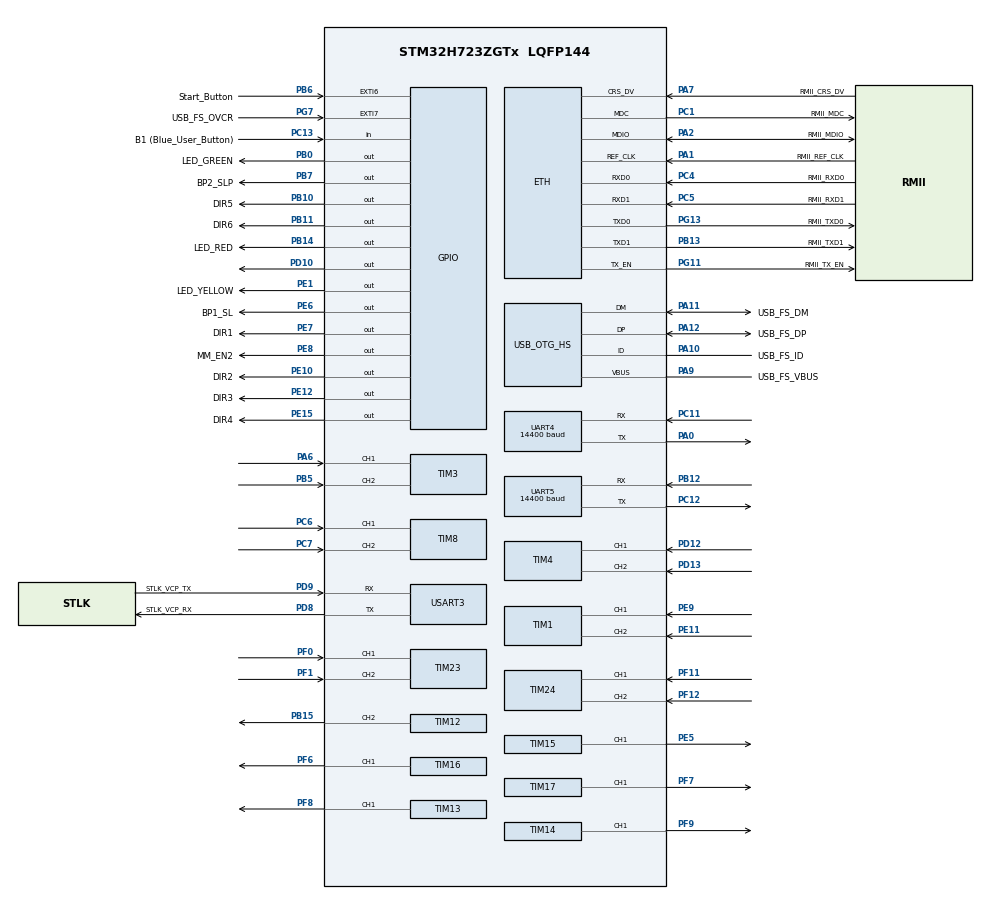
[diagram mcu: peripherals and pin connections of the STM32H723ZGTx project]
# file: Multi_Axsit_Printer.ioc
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Dma.Request0=UART4_RX
Dma.Request1=UART4_TX
Dma.Request2=UART5_RX
Dma.Request3=UART5_TX
Dma.UART4_RX.0.Direction=DMA_PERIPH_TO_MEMORY
Dma.UART4_RX.0.EventEnable=DISABLE
Dma.UART4_RX.0.FIFOMode=DMA_FIFOMODE_DISABLE
Dma.UART4_RX.0.Instance=DMA1_Stream0
Dma.UART4_RX.0.MemDataAlignment=DMA_MDATAALIGN_BYTE
Dma.UART4_RX.0.MemInc=DMA_MINC_ENABLE
Dma.UART4_RX.0.Mode=DMA_NORMAL
Dma.UART4_RX.0.PeriphDataAlignment=DMA_PDATAALIGN_BYTE
Dma.UART4_RX.0.PeriphInc=DMA_PINC_DISABLE
Dma.UART4_RX.0.Polarity=HAL_DMAMUX_REQ_GEN_RISING
Dma.UART4_RX.0.Priority=DMA_PRIORITY_LOW
Dma.UART4_RX.0.RequestNumber=1
Dma.UART4_RX.0.SignalID=NONE
Dma.UART4_RX.0.SyncEnable=DISABLE
Dma.UART4_RX.0.SyncPolarity=HAL_DMAMUX_SYNC_NO_EVENT
Dma.UART4_RX.0.SyncRequestNumber=1
Dma.UART4_RX.0.SyncSignalID=NONE
Dma.UART4_TX.1.Direction=DMA_MEMORY_TO_PERIPH
Dma.UART4_TX.1.EventEnable=DISABLE
Dma.UART4_TX.1.FIFOMode=DMA_FIFOMODE_DISABLE
Dma.UART4_TX.1.Instance=DMA1_Stream1
Dma.UART4_TX.1.MemDataAlignment=DMA_MDATAALIGN_BYTE
Dma.UART4_TX.1.MemInc=DMA_MINC_ENABLE
Dma.UART4_TX.1.Mode=DMA_NORMAL
Dma.UART4_TX.1.PeriphDataAlignment=DMA_PDATAALIGN_BYTE
Dma.UART4_TX.1.PeriphInc=DMA_PINC_DISABLE
Dma.UART4_TX.1.Polarity=HAL_DMAMUX_REQ_GEN_RISING
Dma.UART4_TX.1.Priority=DMA_PRIORITY_LOW
Dma.UART4_TX.1.RequestNumber=1
Dma.UART4_TX.1.SignalID=NONE
Dma.UART4_TX.1.SyncEnable=DISABLE
Dma.UART4_TX.1.SyncPolarity=HAL_DMAMUX_SYNC_NO_EVENT
Dma.UART4_TX.1.SyncRequestNumber=1
Dma.UART4_TX.1.SyncSignalID=NONE
Dma.UART5_RX.2.Direction=DMA_PERIPH_TO_MEMORY
Dma.UART5_RX.2.EventEnable=DISABLE
Dma.UART5_RX.2.FIFOMode=DMA_FIFOMODE_DISABLE
Dma.UART5_RX.2.Instance=DMA1_Stream2
Dma.UART5_RX.2.MemDataAlignment=DMA_MDATAALIGN_BYTE
Dma.UART5_RX.2.MemInc=DMA_MINC_ENABLE
Dma.UART5_RX.2.Mode=DMA_NORMAL
Dma.UART5_RX.2.PeriphDataAlignment=DMA_PDATAALIGN_BYTE
Dma.UART5_RX.2.PeriphInc=DMA_PINC_DISABLE
Dma.UART5_RX.2.Polarity=HAL_DMAMUX_REQ_GEN_RISING
Dma.UART5_RX.2.Priority=DMA_PRIORITY_LOW
Dma.UART5_RX.2.RequestNumber=1
Dma.UART5_RX.2.SignalID=NONE
Dma.UART5_RX.2.SyncEnable=DISABLE
Dma.UART5_RX.2.SyncPolarity=HAL_DMAMUX_SYNC_NO_EVENT
Dma.UART5_RX.2.SyncRequestNumber=1
Dma.UART5_RX.2.SyncSignalID=NONE
Dma.UART5_TX.3.Direction=DMA_MEMORY_TO_PERIPH
Dma.UART5_TX.3.EventEnable=DISABLE
Dma.UART5_TX.3.FIFOMode=DMA_FIFOMODE_DISABLE
Dma.UART5_TX.3.Instance=DMA1_Stream3
Dma.UART5_TX.3.MemDataAlignment=DMA_MDATAALIGN_BYTE
Dma.UART5_TX.3.MemInc=DMA_MINC_ENABLE
Dma.UART5_TX.3.Mode=DMA_NORMAL
Dma.UART5_TX.3.PeriphDataAlignment=DMA_PDATAALIGN_BYTE
Dma.UART5_TX.3.PeriphInc=DMA_PINC_DISABLE
Dma.UART5_TX.3.Polarity=HAL_DMAMUX_REQ_GEN_RISING
Dma.UART5_TX.3.Priority=DMA_PRIORITY_LOW
Dma.UART5_TX.3.RequestNumber=1
Dma.UART5_TX.3.SignalID=NONE
Dma.UART5_TX.3.SyncEnable=DISABLE
Dma.UART5_TX.3.SyncPolarity=HAL_DMAMUX_SYNC_NO_EVENT
Dma.UART5_TX.3.SyncRequestNumber=1
Dma.UART5_TX.3.SyncSignalID=NONE
ETH.MediaInterface=HAL_ETH_RMII_MODE
Mcu.Family=STM32H7
Mcu.Name=STM32H723ZGTx
Mcu.Package=LQFP144
NVIC.DMA1_Stream0_IRQn=true\:0\:0\:false\:false\:true\:false\:true\:true
NVIC.DMA1_Stream1_IRQn=true\:0\:0\:false\:false\:true\:false\:true\:true
NVIC.DMA1_Stream2_IRQn=true\:0\:0\:false\:false\:true\:false\:true\:true
NVIC.DMA1_Stream3_IRQn=true\:0\:0\:false\:false\:true\:false\:true\:true
NVIC.EXTI9_5_IRQn=true\:0\:0\:false\:false\:true\:true\:true\:true
NVIC.PriorityGroup=NVIC_PRIORITYGROUP_4
NVIC.TIM5_IRQn=true\:0\:0\:false\:false\:true\:true\:true\:true
NVIC.UART4_IRQn=true\:0\:0\:false\:false\:true\:true\:true\:true
NVIC.UART5_IRQn=true\:0\:0\:false\:false\:true\:true\:true\:true
PA0.Mode=Asynchronous
PA0.Signal=UART4_TX
PA1.GPIO_Label=RMII_REF_CLK
PA1.Mode=RMII
PA1.Signal=ETH_REF_CLK
PA10.GPIO_Label=USB_FS_ID
PA10.Mode=OTG/Dual-Role-Device-FS
PA10.Signal=USB_OTG_HS_ID
PA11.GPIO_Label=USB_FS_DM
PA11.Mode=OTG/Dual-Role-Device-FS
PA11.Signal=USB_OTG_HS_DM
PA12.GPIO_Label=USB_FS_DP
PA12.Mode=OTG/Dual-Role-Device-FS
PA12.Signal=USB_OTG_HS_DP
PA13(JTMS/SWDIO).GPIO_Label=SWDIO
PA13(JTMS/SWDIO).Mode=Trace_Asynchronous_SW
PA13(JTMS/SWDIO).Signal=DEBUG_JTMS-SWDIO
PA14(JTCK/SWCLK).GPIO_Label=SWCLK
PA14(JTCK/SWCLK).Mode=Trace_Asynchronous_SW
PA14(JTCK/SWCLK).Signal=DEBUG_JTCK-SWCLK
PA2.GPIO_Label=RMII_MDIO
PA2.Mode=RMII
PA2.Signal=ETH_MDIO
PA6.Signal=S_TIM3_CH1
PA7.GPIO_Label=RMII_CRS_DV
PA7.Mode=RMII
PA7.Signal=ETH_CRS_DV
PA9.GPIO_Label=USB_FS_VBUS
PA9.Mode=Activate_VBUS_FS
PA9.Signal=USB_OTG_HS_VBUS
PB0.GPIO_Label=LED_GREEN
PB0.Signal=GPIO_Output
PB10.GPIO_Label=DIR5
PB10.Signal=GPIO_Output
PB11.GPIO_Label=DIR6
PB11.Signal=GPIO_Output
PB12.Mode=Asynchronous
PB12.Signal=UART5_RX
PB13.GPIO_Label=RMII_TXD1
PB13.Mode=RMII
PB13.Signal=ETH_TXD1
PB14.GPIO_Label=LED_RED
PB14.Signal=GPIO_Output
PB15.Signal=S_TIM12_CH2
PB3(JTDO/TRACESWO).GPIO_Label=SWO
PB3(JTDO/TRACESWO).Mode=Trace_Asynchronous_SW
PB3(JTDO/TRACESWO).Signal=DEBUG_JTDO-SWO
PB5.Signal=S_TIM3_CH2
PB6.GPIO_Label=Start_Button
PB6.GPIO_PuPd=GPIO_PULLDOWN
PB6.Signal=GPXTI6
PB7.GPIO_Label=BP2_SLP
PB7.Signal=GPIO_Output
PC1.GPIO_Label=RMII_MDC
PC1.Mode=RMII
PC1.Signal=ETH_MDC
PC11.Mode=Asynchronous
PC11.Signal=UART4_RX
PC12.Mode=Asynchronous
PC12.Signal=UART5_TX
PC13.GPIO_Label=B1 (Blue_User_Button)
PC13.Signal=GPIO_Input
PC14-OSC32_IN.Mode=LSE-External-Oscillator
PC14-OSC32_IN.Signal=RCC_OSC32_IN
PC15-OSC32_OUT.Mode=LSE-External-Oscillator
PC15-OSC32_OUT.Signal=RCC_OSC32_OUT
PC4.GPIO_Label=RMII_RXD0
PC4.Mode=RMII
PC4.Signal=ETH_RXD0
PC5.GPIO_Label=RMII_RXD1
PC5.Mode=RMII
PC5.Signal=ETH_RXD1
PC6.Signal=S_TIM8_CH1
PC7.Signal=S_TIM8_CH2
PD10.Signal=GPIO_Output
PD12.Signal=S_TIM4_CH1
PD13.Signal=S_TIM4_CH2
PD8.GPIO_Label=STLK_VCP_RX
PD8.Mode=Asynchronous
PD8.Signal=USART3_TX
PD9.GPIO_Label=STLK_VCP_TX
PD9.Mode=Asynchronous
PD9.Signal=USART3_RX
PE1.GPIO_Label=LED_YELLOW
PE1.Signal=GPIO_Output
PE10.GPIO_Label=DIR2
PE10.Signal=GPIO_Output
PE11.Signal=S_TIM1_CH2
PE12.GPIO_Label=DIR3
PE12.Signal=GPIO_Output
PE15.GPIO_Label=DIR4
PE15.Signal=GPIO_Output
PE5.Signal=S_TIM15_CH1
PE6.GPIO_Label=BP1_SL
PE6.Signal=GPIO_Output
PE7.GPIO_Label=DIR1
PE7.Signal=GPIO_Output
PE8.GPIO_Label=MM_EN2
PE8.Signal=GPIO_Output
PE9.Signal=S_TIM1_CH1
PF0.Mode=Encoder_Interface
PF0.Signal=TIM23_CH1
PF1.Signal=S_TIM23_CH2
PF11.Mode=Encoder_Interface
PF11.Signal=TIM24_CH1
PF12.Signal=S_TIM24_CH2
PF6.Signal=S_TIM16_CH1
PF7.Signal=S_TIM17_CH1
PF8.Signal=S_TIM13_CH1
PF9.Signal=S_TIM14_CH1
PG11.GPIO_Label=RMII_TX_EN
PG11.Mode=RMII
PG11.Signal=ETH_TX_EN
PG13.GPIO_Label=RMII_TXD0
PG13.Mode=RMII
PG13.Signal=ETH_TXD0
PG7.GPIO_Label=USB_FS_OVCR
PG7.Signal=GPXTI7
PH0-OSC_IN.GPIO_Label=MCO
PH0-OSC_IN.Mode=HSE-External-Clock-Source
PH0-OSC_IN.Signal=RCC_OSC_IN
PH1-OSC_OUT.Signal=RCC_OSC_OUT
ProjectManager.HeapSize=0x200
ProjectManager.StackSize=0x400
ProjectManager.TargetToolchain=STM32CubeIDE
RCC.ADCFreq_Value=76000000
RCC.APB1Freq_Value=137500000
RCC.APB2Freq_Value=137500000
RCC.APB3Freq_Value=137500000
RCC.APB4Freq_Value=137500000
RCC.CortexFreq_Value=550000000
RCC.D1PPRE=RCC_APB3_DIV2
RCC.D2PPRE1=RCC_APB1_DIV2
RCC.D2PPRE2=RCC_APB2_DIV2
RCC.D3PPRE=RCC_APB4_DIV2
RCC.DIVM1=4
RCC.DIVM2=1
RCC.DIVN1=275
RCC.DIVN2=19
RCC.DIVP1=1
RCC.DIVQ1=4
RCC.HCLKFreq_Value=275000000
RCC.HPRE=RCC_HCLK_DIV2
RCC.HSE_VALUE=8000000
RCC.PLLFRACN=0
RCC.PLLSourceVirtual=RCC_PLLSOURCE_HSE
RCC.SYSCLKFreq_VALUE=550000000
RCC.SYSCLKSource=RCC_SYSCLKSOURCE_PLLCLK
RCC.USBCLockSelection=RCC_USBCLKSOURCE_HSI48
RCC.USBFreq_Value=48000000
SH.S_TIM12_CH2.0=TIM12_CH2,PWM Generation2 CH2
SH.S_TIM13_CH1.0=TIM13_CH1,PWM Generation1 CH1
SH.S_TIM14_CH1.0=TIM14_CH1,PWM Generation1 CH1
SH.S_TIM15_CH1.0=TIM15_CH1,PWM Generation1 CH1
SH.S_TIM16_CH1.0=TIM16_CH1,PWM Generation1 CH1
SH.S_TIM17_CH1.0=TIM17_CH1,PWM Generation1 CH1
SH.S_TIM1_CH1.0=TIM1_CH1,Encoder_Interface
SH.S_TIM1_CH2.0=TIM1_CH2,Encoder_Interface
SH.S_TIM23_CH2.0=TIM23_CH2,Encoder_Interface
SH.S_TIM24_CH2.0=TIM24_CH2,Encoder_Interface
SH.S_TIM3_CH1.0=TIM3_CH1,Encoder_Interface
SH.S_TIM3_CH2.0=TIM3_CH2,Encoder_Interface
SH.S_TIM4_CH1.0=TIM4_CH1,Encoder_Interface
SH.S_TIM4_CH2.0=TIM4_CH2,Encoder_Interface
SH.S_TIM8_CH1.0=TIM8_CH1,Encoder_Interface
SH.S_TIM8_CH2.0=TIM8_CH2,Encoder_Interface
TIM1.EncoderMode=TIM_ENCODERMODE_TI12
TIM12.Channel-PWM\ Generation2\ CH2=TIM_CHANNEL_2
TIM12.Period=1250-1
TIM12.Prescaler=11-1
TIM13.Channel=TIM_CHANNEL_1
TIM13.Period=1250-1
TIM13.Prescaler=11-1
TIM14.Channel=TIM_CHANNEL_1
TIM14.Period=1250-1
TIM14.Prescaler=440-1
TIM15.Channel-PWM\ Generation1\ CH1=TIM_CHANNEL_1
TIM15.Period=1250-1
TIM15.Prescaler=440-1
TIM16.Channel=TIM_CHANNEL_1
TIM16.Period=1250-1
TIM16.Prescaler=440-1
TIM17.Channel=TIM_CHANNEL_1
TIM17.Period=1250-1
TIM17.Prescaler=440-1
TIM23.EncoderMode=TIM_ENCODERMODE_TI12
TIM24.EncoderMode=TIM_ENCODERMODE_TI12
TIM3.EncoderMode=TIM_ENCODERMODE_TI12
TIM4.EncoderMode=TIM_ENCODERMODE_TI12
TIM5.Period=49999
TIM5.Prescaler=274
TIM8.EncoderMode=TIM_ENCODERMODE_TI12
UART4.BaudRate=14400
UART5.BaudRate=14400
USART3.VirtualMode-Asynchronous=VM_ASYNC
VP_MEMORYMAP_VS_MEMORYMAP.Mode=CurAppReg
VP_TIM13_VS_ClockSourceINT.Mode=Enable_Timer
VP_TIM14_VS_ClockSourceINT.Mode=Enable_Timer
VP_TIM16_VS_ClockSourceINT.Mode=Enable_Timer
VP_TIM17_VS_ClockSourceINT.Mode=Enable_Timer
VP_TIM5_VS_ClockSourceINT.Mode=Internal
board=NUCLEO-H723ZG

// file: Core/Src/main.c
/* USER CODE BEGIN Header */
/**
 ******************************************************************************
 * @file           : main.c
 * @brief          : Main program body
 ******************************************************************************
 * @attention
 *
 * Copyright (c) 2024 STMicroelectronics.
 * All rights reserved.
 *
 * This software is licensed under terms that can be found in the LICENSE file
 * in the root directory of this software component.
 * If no LICENSE file comes with this software, it is provided AS-IS.
 *
 ******************************************************************************
 */
/* USER CODE END Header */
#include "main.h"
#include "dma.h"
#include "eth.h"
#include "memorymap.h"
#include "tim.h"
#include "usart.h"
#include "usb_otg.h"
#include "gpio.h"

/* USER CODE BEGIN Includes */
#include "mainpp.h"
/* USER CODE END Includes */

void SystemClock_Config(void);

/* USER CODE BEGIN 0 */
int _write(int file, char *ptr, int len) {
	for (int i = 0; i < len; i++) ITM_SendChar((*ptr++));
	return len;
}
/* USER CODE END 0 */

int main(void)
{

  /* MCU Configuration--------------------------------------------------------*/

  /* Reset of all peripherals, Initializes the Flash interface and the Systick. */
  HAL_Init();

  /* Configure the system clock */
  SystemClock_Config();

  /* Initialize all configured peripherals */
  MX_GPIO_Init();
  MX_DMA_Init();
  MX_USB_OTG_HS_USB_Init();
  MX_UART4_Init();
  MX_ETH_Init();
  MX_TIM1_Init();
  MX_TIM3_Init();
  MX_TIM4_Init();
  MX_TIM8_Init();
  MX_TIM13_Init();
  MX_TIM14_Init();
  MX_TIM15_Init();
  MX_TIM16_Init();
  MX_TIM17_Init();
  MX_TIM23_Init();
  MX_TIM24_Init();
  MX_TIM12_Init();
  MX_USART3_UART_Init();
  MX_UART5_Init();
  MX_TIM5_Init();
  /* USER CODE BEGIN 2 */
	main_function();
  /* USER CODE END 2 */

  /* Infinite loop */
	while (1) {

	}
}

void SystemClock_Config(void)
{
  RCC_OscInitTypeDef RCC_OscInitStruct = {0};
  RCC_ClkInitTypeDef RCC_ClkInitStruct = {0};

  /** Supply configuration update enable
  */
  HAL_PWREx_ConfigSupply(PWR_LDO_SUPPLY);

  /** Configure the main internal regulator output voltage
  */
  __HAL_PWR_VOLTAGESCALING_CONFIG(PWR_REGULATOR_VOLTAGE_SCALE0);

  while(!__HAL_PWR_GET_FLAG(PWR_FLAG_VOSRDY)) {}

  /** Initializes the RCC Oscillators according to the specified parameters
  * in the RCC_OscInitTypeDef structure.
  */
  RCC_OscInitStruct.OscillatorType = RCC_OSCILLATORTYPE_HSI48|RCC_OSCILLATORTYPE_HSE;
  RCC_OscInitStruct.HSEState = RCC_HSE_BYPASS;
  RCC_OscInitStruct.HSI48State = RCC_HSI48_ON;
  RCC_OscInitStruct.PLL.PLLState = RCC_PLL_ON;
  RCC_OscInitStruct.PLL.PLLSource = RCC_PLLSOURCE_HSE;
  RCC_OscInitStruct.PLL.PLLM = 4;
  RCC_OscInitStruct.PLL.PLLN = 275;
  RCC_OscInitStruct.PLL.PLLP = 1;
  RCC_OscInitStruct.PLL.PLLQ = 4;
  RCC_OscInitStruct.PLL.PLLR = 2;
  RCC_OscInitStruct.PLL.PLLRGE = RCC_PLL1VCIRANGE_1;
  RCC_OscInitStruct.PLL.PLLVCOSEL = RCC_PLL1VCOWIDE;
  RCC_OscInitStruct.PLL.PLLFRACN = 0;
  if (HAL_RCC_OscConfig(&RCC_OscInitStruct) != HAL_OK)
  {
    Error_Handler();
  }

  /** Initializes the CPU, AHB and APB buses clocks
  */
  RCC_ClkInitStruct.ClockType = RCC_CLOCKTYPE_HCLK|RCC_CLOCKTYPE_SYSCLK
                              |RCC_CLOCKTYPE_PCLK1|RCC_CLOCKTYPE_PCLK2
                              |RCC_CLOCKTYPE_D3PCLK1|RCC_CLOCKTYPE_D1PCLK1;
  RCC_ClkInitStruct.SYSCLKSource = RCC_SYSCLKSOURCE_PLLCLK;
  RCC_ClkInitStruct.SYSCLKDivider = RCC_SYSCLK_DIV1;
  RCC_ClkInitStruct.AHBCLKDivider = RCC_HCLK_DIV2;
  RCC_ClkInitStruct.APB3CLKDivider = RCC_APB3_DIV2;
  RCC_ClkInitStruct.APB1CLKDivider = RCC_APB1_DIV2;
  RCC_ClkInitStruct.APB2CLKDivider = RCC_APB2_DIV2;
  RCC_ClkInitStruct.APB4CLKDivider = RCC_APB4_DIV2;

  if (HAL_RCC_ClockConfig(&RCC_ClkInitStruct, FLASH_LATENCY_3) != HAL_OK)
  {
    Error_Handler();
  }
}

void Error_Handler(void)
{
	__disable_irq();
	while (1) {
	}
}
